# layer3_tx_model: IP-XACT component
VLNV IcronTechnologies:IcronTechnologies:layer3_tx_model:1.0

## Parameters
addr_width = 8
bus_width = 32

## Bus interfaces (logical=physical port)
default_map: slave AGNISYS:AGNISYS:APB:1.0, memory map layer3_txmap
  pclk=pclk, presetn=presetn, psel=psel, penable=penable, pwrite=pwrite, pprot=pprot, pstrb=pstrb, pwdata=pwdata, paddr=paddr, pready=pready, prdata=prdata, pslverr=pslverr

## Ports
in pclk
in presetn
in psel
in penable
in pwrite
in pprot[2:0]
in pstrb[(bus_width div 8 )-1:0]
in pwdata[bus_width -1:0]
in paddr[addr_width -1:0]
out pready
out prdata[bus_width -1:0]
out pslverr
out layer3_tx_regsversion_major_r[7:0]
out layer3_tx_regsversion_minor_r[7:0]
out layer3_tx_regsversion_patch_r[7:0]
out layer3_tx_regseth_framer_config0_max_byte_enb
out layer3_tx_regseth_framer_config0_max_byte_max_byte_r[13:0]
out layer3_tx_regseth_framer_config0_mac_dg_type_enb
out layer3_tx_regseth_framer_config0_mac_dg_type_mac_dg_type_r[7:0]
out layer3_tx_regseth_framer_config0_timer_wait_enb
out layer3_tx_regseth_framer_config0_timer_wait_timer_wait_r[11:0]
out layer3_tx_regseth_framer_config0_mtu_size_enb
out layer3_tx_regseth_framer_config0_mtu_size_mtu_size_r[13:0]
out layer3_tx_regseth_framer_stats0_rd2clr_config_rd_valid_out
out layer3_tx_regseth_framer_stats0_rd2clr_config_wr_valid_out
out layer3_tx_regseth_framer_stats0_out_eop_rd_valid_out
out layer3_tx_regseth_framer_stats0_out_sop_rd_valid_out
out layer3_tx_regseth_framer_stats0_inbuff_eop_rd_valid_out
out layer3_tx_regseth_framer_stats0_inbuff_sop_rd_valid_out
out layer3_tx_regseth_framer_stats0_in_eop_rd_valid_out
out layer3_tx_regseth_framer_stats0_in_sop_rd_valid_out
out layer3_tx_regseth_framer_stats0_mac_dg_size_err_rd_valid_out
out layer3_tx_regseth_framer_pfifo_write_engine_config0_clear_enb
out layer3_tx_regseth_framer_pfifo_write_engine_config0_clear_wclr_r
out layer3_tx_regseth_framer_pfifo_write_engine_config0_mode_enb
out layer3_tx_regseth_framer_pfifo_write_engine_config0_mode_drp_on_sop_r
out layer3_tx_regseth_framer_pfifo_write_engine_config0_mode_drp_on_pkt_err_r
out layer3_tx_regseth_framer_pfifo_write_engine_config0_mode_pkt_strm_r
out layer3_tx_regseth_framer_pfifo_write_engine_config0_mode_flw_ctrl_en_r
out layer3_tx_regseth_framer_pfifo_write_engine_config0_notify_limit_enb
out layer3_tx_regseth_framer_pfifo_write_engine_config0_notify_limit_ntfy_lmt_r[31:0]
out layer3_tx_regseth_framer_pfifo_write_engine_stats0_rd2clr_config_rd_valid_out
out layer3_tx_regseth_framer_pfifo_write_engine_stats0_rd2clr_config_wr_valid_out
out layer3_tx_regseth_framer_pfifo_write_engine_stats0_nfifo_dcount_rd_valid_out
out layer3_tx_regseth_framer_pfifo_write_engine_stats0_pfifo_dcount_rd_valid_out
out layer3_tx_regseth_framer_pfifo_write_engine_stats0_pkt_max_byte_cnt_err_rd_valid_out
out layer3_tx_regseth_framer_pfifo_write_engine_stats0_fifo_full_err_rd_valid_out
out layer3_tx_regseth_framer_pfifo_write_engine_stats0_pkt_err_rd_valid_out
out layer3_tx_regseth_framer_pfifo_write_engine_stats0_pkt_sop_err_rd_valid_out
out layer3_tx_regseth_framer_pfifo_write_engine_stats0_wflush_act_rd_valid_out
out layer3_tx_regseth_framer_pfifo_write_engine_stats0_drp_pkt_rd_rd_valid_out
out layer3_tx_regseth_framer_pfifo_write_engine_stats0_drp_pkt_wr_rd_valid_out
out layer3_tx_regseth_framer_pfifo_write_engine_stats0_flow_ctrl_rd_valid_out
out layer3_tx_regseth_framer_pfifo_read_engine_config0_clear_enb
out layer3_tx_regseth_framer_pfifo_read_engine_config0_clear_rclr_r
out layer3_tx_regseth_framer_pfifo_read_engine_stats0_rd2clr_config_rd_valid_out
out layer3_tx_regseth_framer_pfifo_read_engine_stats0_rd2clr_config_wr_valid_out
out layer3_tx_regseth_framer_pfifo_read_engine_stats0_rflush_act_rd_valid_out
out layer3_tx_regseth_framer_pfifo_read_engine_stats0_drp_pkt_rd_valid_out
out layer3_tx_regseth_framer_pfifo_read_engine_stats0_flow_ctrl_rd_valid_out
out layer3_tx_regseth_framer_ptp_guard_config0_fix_ptp_violations_enb
out layer3_tx_regseth_framer_ptp_guard_config0_fix_ptp_violations_activate_r
out layer3_tx_regseth_framer_ptp_guard_config0_max_cycles_enb
out layer3_tx_regseth_framer_ptp_guard_config0_max_cycles_max_cycle_mode_r[3:0]
out layer3_tx_regseth_framer_ptp_guard_config0_max_cycles_max_cycles_r[15:0]
out layer3_tx_regseth_framer_ptp_guard_stats0_rd2clr_config_rd_valid_out
out layer3_tx_regseth_framer_ptp_guard_stats0_rd2clr_config_wr_valid_out
out layer3_tx_regseth_framer_ptp_guard_stats0_missing_sop_err_rd_valid_out
out layer3_tx_regseth_framer_ptp_guard_stats0_missing_eop_err_rd_valid_out
out layer3_tx_regseth_framer_ptp_guard_stats0_max_cycle_err_rd_valid_out

## Address spaces and blocks
layer3_txmap.layer3_tx: base 0x000, range 0x100, width 32

## Registers
Registers are 32-bit, read-only, reset 0x0 unless marked. A register's access mark holds for its fields unless they carry their own. Offsets are from the block's base; lines under a group give offsets from that group; [hi:lo] are bit positions; {n}, {i} and the like mark numbered series; 'fields as' and 'values as' point back to an identical list; <NAME> marks a mode.

## layer3_txmap.layer3_tx — Layer 3 Registers
Base 0x00000000
0x00 version reset 0x40200 — 4.1.0: Changed the Interrupt Pending to avoid blocking the register update when enable is 0 4.2.0: Added pending_irq register
  [23:16] major — Major version
  [15:8] minor — Minor version
  [7:0] patch — Patch version
0x04 eth_framer group
  0x00 version reset 0x30000
    fields as version
  0x04 config0 group
    0x00 max_byte rw reset 0x80 — Maximum bytes in incoming PTP bytes
      [13:0] max_byte
    0x04 mac_dg_type rw reset 0x4 — MAC Datagram Type used in the out PTP
      [7:0] mac_dg_type
    0x08 timer_wait rw — Maximum number of clock cycles that is allowed to hold a new incoming PTP before it is put into a MAC Datagram if the input PTPs are not back-to-back and the downstream is not busy. The timer starts when a new PTP is received. This timer gives a control of aggregating input PTPs that are gapped. Note: A value of 0x0 instructs the logic to not wait for input PTPs if they are gapped, unless the downstream is busy in which case the logic will always wait for gapped input PTPs unless the next PTP has the "potential" to go over the MTU size
      [11:0] timer_wait
    0x0C mtu_size rw reset 0x5DC — This is the MTU size to use. Note that the FPGA build must have been built with the highest of normal MTU=1500 or Jumbo MTU=9000 (see max_mtu_size). Accordingly, this value should be less than that.
      [13:0] mtu_size
    0x10 max_mtu_size reset 0x5DC — This is the MTU size used during the FPGA build.
      [13:0] max_mtu_size
  0x18 stats0 group — All the Statistic Registers and their configuration.
    0x00 rd2clr_config rw — Configures if the stats register read by s/w clears the read register. A 1 in any bit configures the h/w to clear the corresponding stats register after a s/w read of that stats register.
      [6] mac_dg_size_err, [5] in_sop, [4] in_eop, [3] inbuff_sop, [2] inbuff_eop, [1] out_sop, [0] out_eop
    0x04 out_eop — Count of the PTP EOP seen on the output port
    0x08 out_sop — Count of the PTP SOP seen on the output port
    0x0C inbuff_eop — Count of the EOP of the PTP packets seen at the buffer
    0x10 inbuff_sop — Count of the EOP of the PTP packets seen at the buffer
    0x14 in_eop — Count of the EOP of the PTP packets on the input port
    0x18 in_sop — Count of the EOP of the PTP packets on the input port
    0x1C mac_dg_size_err — Count of the MAC DataGram Size Calculation Error. This does not role over when reached its maximum
      [7:0] mac_dg_size_err
  0x38 pfifo group
    0x00 version reset 0x10100 — Version 1.1.0: Added Icron Attributes for stats script generation
      fields as version
    0x04 write_engine group
      0x00 config0 group
        0x00 clear rw — Synchronous clear for the write clock domain
          [0] wclr
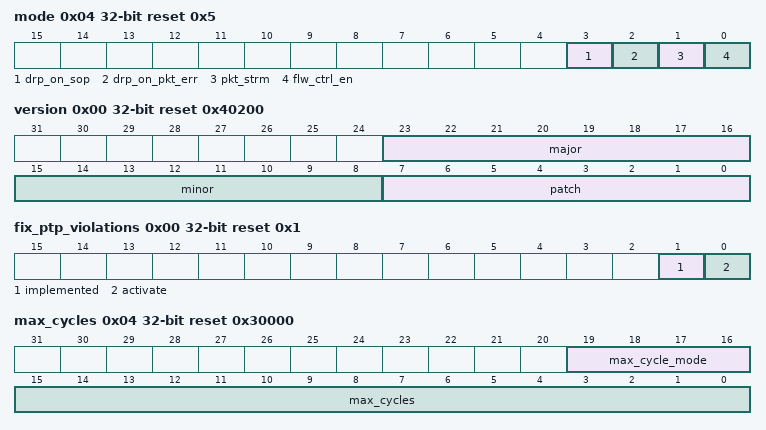
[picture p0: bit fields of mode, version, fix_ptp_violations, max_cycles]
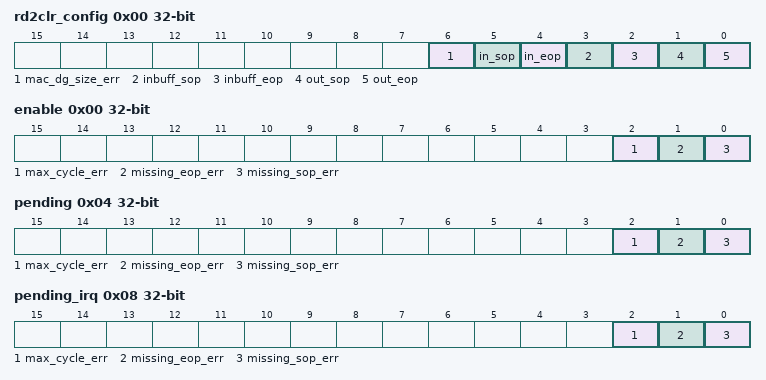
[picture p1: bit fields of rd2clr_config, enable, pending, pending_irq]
        0x04 mode rw reset 0x5
          [3] drp_on_sop — When set, drops the current packet without writing it to the buffer. See Wiki
          [2] drp_on_pkt_err — When set, removes the packet from the buffer without presenting it to the output interface upon the ERR bit being set before the notification point. See Wiki
          [1] pkt_strm — Selects packet based or streaming based behavior. See Wiki
          [0] flw_ctrl_en — Enables the flow control. See Wiki
        0x08 notify_limit rw
          [31:0] ntfy_lmt — Sets the number of words required to be written into the packet FIFO before a notification will be generated. See wiki
      0x0C stats0 group — All the Statistic Registers and their configuration for the Write Engine
        0x00 rd2clr_config rw — Configures if the stats register read by s/w clears the read register. A 1 in any bit configures the h/w to clear the corresponding stats register after a s/w read of that stats register.
          [9] flow_ctrl, [8] drp_pkt_wr, [7] drp_pkt_rd, [6] wflush_act, [5] pkt_sop_err, [4] pkt_err, [3] fifo_full_err, [2] pkt_max_byte_cnt_err, [1] pfifo_dcount, [0] nfifo_dcount
        0x04 nfifo_dcount — Current level for the notification FIFO in the PFIFO
          [15:0] nfifo_dcount — _icron_water_marker_ _icron_no_counter_
        0x08 pfifo_dcount — Current level for the packet FIFO in the PFIFO
          [15:0] pfifo_dcount — _icron_water_marker_ _icron_no_counter_
        0x0C pkt_max_byte_cnt_err — The count for capped packets in PFIFO write engine, as the result of reaching maximum size in the PFIFO
          [7:0] pkt_max_byte_cnt_err
        0x10 fifo_full_err — The count for either of PFIFO or NFIFO being full
          [7:0] fifo_full_err
        0x14 pkt_err — The count of packets tagged to be dropped later in the PFIFO read engine
          [7:0] pkt_err
        0x18 pkt_sop_err — The count of packets flushed in the PFIFO during the SOP phase
          [7:0] pkt_sop_err
        0x1C wflush_act — The count of capped packets in the PFIFO. Note that back-to-back packets are counted as one if they are both capped.
          [7:0] wflush_act — _icron_event_detect_rising_edge_
        0x20 drp_pkt_rd — The count of drop packets flagged to be dropped by the read engine
          [7:0] drp_pkt_rd
        0x24 drp_pkt_wr — The count of drop packets by the write engine
          [7:0] drp_pkt_wr
        0x28 flow_ctrl — The count of the clock cycles the DRDY is asserted low resulting in flow control
          [15:0] flow_ctrl
    0x3C read_engine group
      0x00 config0 group
        0x00 clear rw — Synchronous clear for the read clock domain
          [0] rclr
      0x04 stats0 group — All the Statistic Registers and their configuration for the Read Engine
        0x00 rd2clr_config rw — Configures if the stats register read by s/w clears the read register. A 1 in any bit configures the h/w to clear the corresponding stats register after a s/w read of that stats register.
          [2] flow_ctrl, [1] drp_pkt, [0] rflush_act
        0x04 rflush_act — The counts of number of packets flushed from the PFIFO.
          [7:0] rflush_act — _icron_event_detect_rising_edge_
        0x08 drp_pkt — The counts of drop packet in the PFIFO read engine
          [7:0] drp_pkt
        0x0C flow_ctrl — The count of the clock cycles the DRDY is asserted low resulting in flow control
          [15:0] flow_ctrl
  0x88 ptp_guard group
    0x00 version reset 0x30300 — 3.1.0: Fixed bug in Max Cycle Error where in certain mode the cycles were included in the count 3.2.0: Changed the Interrupt Pending to avoid blocking the register update when enable is 0 3.3.0: Added pending_irq register
      fields as version
    0x04 config0 group
      0x00 fix_ptp_violations access per field reset 0x1
        [1] implemented ro — This is the synthesis parameter value used. When 1, it shows the PTP Guard fix logic has been implemented
        [0] activate rw — When 1, and if the fix logic is implemented, it instructs the PTP Guard to fix the PTP violations it detects (and reports). Note that there is a synthesis parameter to generate the "fix" logic or not When 0, no attempt is done to fix (even if the logic exists) and the PTP Guard will only work as a monitor and reports the violations detected. For full details of the operation, what violations are detected and fixed, and how the fix is done, see the wiki.
      0x04 max_cycles rw reset 0x30000
        [19:16] max_cycle_mode — This configures the mode of counting towards max_cycles: 0x0: All PTP cycles are included in the count 0x1: PTP cycles with backpressure (drdy=1'b0) are excluded from the count 0x2: PTP cycles with wait (srdy=1'b0) are excluded from the count 0x3: PTP cycles with either backpressure or wait are excluded from the count. Hence, only "absorbed" PTP cycles are included in the count Other mode values are reserved
        [15:0] max_cycles — Sets the maximum number of clock cycles the PTP packet can last between its sop and eop taking into account the max_cycle_mode When set to 0, it instructs the logic not to fix this violation (when the fix logic is available). However, the monitor will still issue a violation when the cycle count reaches its maximum and rollover.
    0x0C stats0 group — All the Statistic Registers and their configuration
      0x00 rd2clr_config rw — Configures if the stats register read by s/w clears the read register. A 1 in any bit configures the h/w to clear the corresponding stats register after a s/w read of that stats register.
        [2] max_cycle_err, [1] missing_eop_err, [0] missing_sop_err
      0x04 missing_sop_err — Counts the number of PTP violations due to missing sop where the srdy was asserted without a prior sop assertion
        [15:0] missing_sop_err
      0x08 missing_eop_err — Counts the number of PTP violations due to missing eop where the PTP had been started but a new sop is seen without ending the previously started PTP
        [15:0] missing_eop_err
      0x0C max_cycle_err — Counts the number of PTP violations due to reaching the maximum allowed cycles after starting a new PTP
        [15:0] max_cycle_err
    0x1C irq0 group — Define the IRQ group
      0x00 enable rw — The enable for the actual interrupt signals. Writing a 1 enables the interrupt.
        [2] max_cycle_err — Fires on PTP violations due to reaching the maximum allowed cycles after starting a new PTP
        [1] missing_eop_err — Fires on PTP violations due to missing eop where the PTP had been started but a new sop is seen without ending the previously started PTP
        [0] missing_sop_err — Fires on PTP violations due to missing sop where the srdy was asserted without a prior sop assertion
      0x04 pending rw — The actual interrupt(s) that has triggered. Write a 1 to clear.
        [2] max_cycle_err write-1-clears, [1] missing_eop_err write-1-clears, [0] missing_sop_err write-1-clears
      0x08 pending_irq — Registered version of pending & enable.
        [2] max_cycle_err, [1] missing_eop_err, [0] missing_sop_err
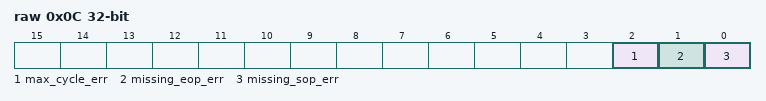
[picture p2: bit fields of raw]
      0x0C raw — The status registered values for the interrupt signals, if applicable.
        [2] max_cycle_err — Not used
        [1] missing_eop_err — Not used
        [0] missing_sop_err — Not used
0xB8 irq0 group — Define the IRQ group
  0x00 enable rw — Indicating a rollover for that particular count has occurred
    [18] framer_stats0_out_eop_irq_rollover, [17] framer_stats0_out_sop_irq_rollover, [16] framer_stats0_inbuff_eop_irq_rollover, [15] framer_stats0_inbuff_sop_irq_rollover, [14] framer_stats0_in_eop_irq_rollover, [13] framer_stats0_in_sop_irq_rollover, [12] framer_pfifo_write_engine_stats0_nfifo_dcount_irq_rollover, [11] framer_pfifo_write_engine_stats0_pfifo_dcount_irq_rollover, [10] framer_pfifo_write_engine_stats0_pkt_max_byte_cnt_err_irq_rollover, [9] framer_pfifo_write_engine_stats0_fifo_full_err_irq_rollover, [8] framer_pfifo_write_engine_stats0_pkt_err_irq_rollover, [7] framer_pfifo_write_engine_stats0_pkt_sop_err_irq_rollover, [6] framer_pfifo_write_engine_stats0_wflush_act_irq_rollover, [5] framer_pfifo_write_engine_stats0_drp_pkt_rd_irq_rollover, [4] framer_pfifo_write_engine_stats0_drp_pkt_wr_irq_rollover, [3] framer_pfifo_write_engine_stats0_flow_ctrl_irq_rollover, [2] framer_pfifo_read_engine_stats0_rflush_act_irq_rollover, [1] framer_pfifo_read_engine_stats0_drp_pkt_irq_rollover, [0] framer_pfifo_read_engine_stats0_flow_ctrl_irq_rollover
  0x04 pending rw — Indicating a rollover for that particular count has occurred
    [18] framer_stats0_out_eop_irq_rollover write-1-clears, [17] framer_stats0_out_sop_irq_rollover write-1-clears, [16] framer_stats0_inbuff_eop_irq_rollover write-1-clears, [15] framer_stats0_inbuff_sop_irq_rollover write-1-clears, [14] framer_stats0_in_eop_irq_rollover write-1-clears, [13] framer_stats0_in_sop_irq_rollover write-1-clears, [12] framer_pfifo_write_engine_stats0_nfifo_dcount_irq_rollover write-1-clears, [11] framer_pfifo_write_engine_stats0_pfifo_dcount_irq_rollover write-1-clears, [10] framer_pfifo_write_engine_stats0_pkt_max_byte_cnt_err_irq_rollover write-1-clears, [9] framer_pfifo_write_engine_stats0_fifo_full_err_irq_rollover write-1-clears, [8] framer_pfifo_write_engine_stats0_pkt_err_irq_rollover write-1-clears, [7] framer_pfifo_write_engine_stats0_pkt_sop_err_irq_rollover write-1-clears, [6] framer_pfifo_write_engine_stats0_wflush_act_irq_rollover write-1-clears, [5] framer_pfifo_write_engine_stats0_drp_pkt_rd_irq_rollover write-1-clears, [4] framer_pfifo_write_engine_stats0_drp_pkt_wr_irq_rollover write-1-clears, [3] framer_pfifo_write_engine_stats0_flow_ctrl_irq_rollover write-1-clears, [2] framer_pfifo_read_engine_stats0_rflush_act_irq_rollover write-1-clears, [1] framer_pfifo_read_engine_stats0_drp_pkt_irq_rollover write-1-clears, [0] framer_pfifo_read_engine_stats0_flow_ctrl_irq_rollover write-1-clears
  0x08 pending_irq — Registered version of pending & enable
    fields as irq0.enable
  0x0C raw — Indicating a rollover for that particular count has occurred
    fields as irq0.enable
